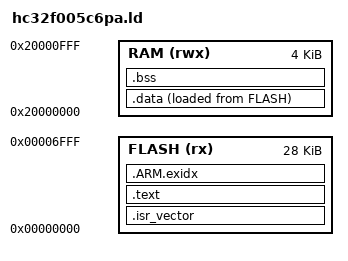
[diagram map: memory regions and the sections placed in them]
ENTRY(Reset_Handler)

MEMORY
{
    FLASH (rx)  : ORIGIN = 0x00000000, LENGTH = 0x00007000
    RAM   (rwx) : ORIGIN = 0x20000000, LENGTH = 0x00001000
}

_estack = ORIGIN(RAM) + LENGTH(RAM);

SECTIONS
{
    .isr_vector :
    {
        . = ALIGN(256);
        KEEP(*(.isr_vector))
        . = ALIGN(4);
    } > FLASH

    .text :
    {
        . = ALIGN(4);
        *(.text*)
        *(.rodata*)
        KEEP(*(.firmware_info))
        *(.glue_7)
        *(.glue_7t)
        . = ALIGN(4);
        _etext = .;
    } > FLASH

    .ARM.exidx :
    {
        . = ALIGN(4);
        *(.ARM.exidx*)
        . = ALIGN(4);
    } > FLASH

    _sidata = LOADADDR(.data);

    .data :
    {
        . = ALIGN(4);
        _sdata = .;
        *(.data*)
        . = ALIGN(4);
        _edata = .;
    } > RAM AT > FLASH

    .bss (NOLOAD) :
    {
        . = ALIGN(4);
        _sbss = .;
        *(.bss*)
        *(COMMON)
        . = ALIGN(4);
        _ebss = .;
    } > RAM

    /DISCARD/ :
    {
        *(.comment)
        *(.note*)
        *(.eh_frame*)
    }
}

ASSERT(_ebss <= ORIGIN(RAM) + LENGTH(RAM), "RAM overflow")
ASSERT(SIZEOF(.isr_vector) + SIZEOF(.text) + SIZEOF(.ARM.exidx) + SIZEOF(.data) <= LENGTH(FLASH), "application overlaps reserved storage")
